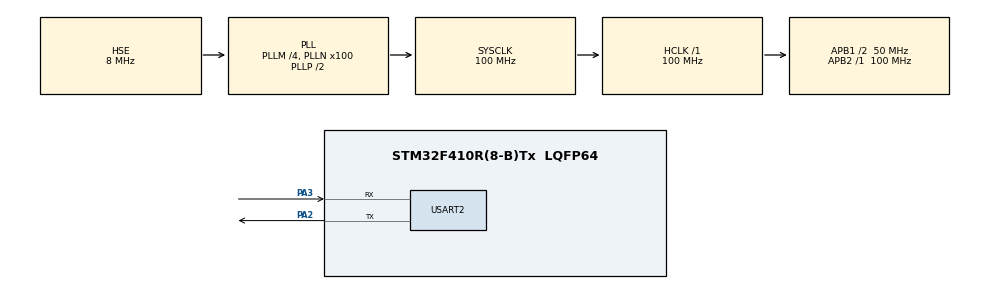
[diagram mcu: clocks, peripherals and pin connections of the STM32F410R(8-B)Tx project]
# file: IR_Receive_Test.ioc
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Mcu.Family=STM32F4
Mcu.Name=STM32F410R(8-B)Tx
Mcu.Package=LQFP64
NVIC.PriorityGroup=NVIC_PRIORITYGROUP_4
NVIC.TIM6_DAC_IRQn=true\:0\:0\:false\:false\:true\:true\:true
PA13.Mode=Serial_Wire
PA13.Signal=SYS_JTMS-SWDIO
PA14.Mode=Serial_Wire
PA14.Signal=SYS_JTCK-SWCLK
PA2.Mode=Asynchronous
PA2.Signal=USART2_TX
PA3.Mode=Asynchronous
PA3.Signal=USART2_RX
PC14-OSC32_IN.Mode=LSE-External-Oscillator
PC14-OSC32_IN.Signal=RCC_OSC32_IN
PC15-OSC32_OUT.Mode=LSE-External-Oscillator
PC15-OSC32_OUT.Signal=RCC_OSC32_OUT
PH0\ -\ OSC_IN.Mode=HSE-External-Oscillator
PH0\ -\ OSC_IN.Signal=RCC_OSC_IN
PH1\ -\ OSC_OUT.Mode=HSE-External-Oscillator
PH1\ -\ OSC_OUT.Signal=RCC_OSC_OUT
ProjectManager.HeapSize=0x200
ProjectManager.StackSize=0x400
ProjectManager.TargetToolchain=SW4STM32
RCC.48MHZClocksFreq_Value=50000000
RCC.AHBFreq_Value=100000000
RCC.APB1CLKDivider=RCC_HCLK_DIV2
RCC.APB1Freq_Value=50000000
RCC.APB1TimFreq_Value=100000000
RCC.APB2Freq_Value=100000000
RCC.APB2TimFreq_Value=100000000
RCC.CortexFreq_Value=100000000
RCC.HCLKFreq_Value=100000000
RCC.HSE_VALUE=8000000
RCC.HSI_VALUE=16000000
RCC.PLLM=4
RCC.PLLN=100
RCC.PLLSourceVirtual=RCC_PLLSOURCE_HSE
RCC.SYSCLKFreq_VALUE=100000000
RCC.SYSCLKSource=RCC_SYSCLKSOURCE_PLLCLK
RCC.VCOOutputFreq_Value=200000000
TIM6.AutoReloadPreload=TIM_AUTORELOAD_PRELOAD_ENABLE
TIM6.Period=9999
USART2.VirtualMode=VM_ASYNC
VP_TIM6_VS_ClockSourceINT.Mode=Enable_Timer
board=custom

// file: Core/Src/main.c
/* USER CODE BEGIN Header */
/**
  ******************************************************************************
  * @file           : main.c
  * @brief          : Main program body
  ******************************************************************************
  * @attention
  *
  * <h2><center>&copy; Copyright (c) 2021 STMicroelectronics.
  * All rights reserved.</center></h2>
  *
  * This software component is licensed by ST under BSD 3-Clause license,
  * the "License"; You may not use this file except in compliance with the
  * License. You may obtain a copy of the License at:
  *                        opensource.org/licenses/BSD-3-Clause
  *
  ******************************************************************************
  */
/* USER CODE END Header */
#include "main.h"

TIM_HandleTypeDef htim6;

UART_HandleTypeDef huart2;

void SystemClock_Config(void);
static void MX_GPIO_Init(void);
static void MX_TIM6_Init(void);
static void MX_USART2_UART_Init(void);

/* USER CODE BEGIN 0 */
#include <errno.h>
#include <sys/stat.h>
#include <sys/times.h>
#include <sys/unistd.h>
int _write(int file, char *ptr, int len) {
    HAL_StatusTypeDef xStatus;
    switch (file) {
    case STDOUT_FILENO: /*stdout*/
		xStatus = HAL_UART_Transmit(&huart2, (uint8_t*)ptr, len, HAL_MAX_DELAY);
		if (xStatus != HAL_OK) {
			errno = EIO;
			return -1;
		}
        break;
    case STDERR_FILENO: /* stderr */
		xStatus = HAL_UART_Transmit(&huart2, (uint8_t*)ptr, len, HAL_MAX_DELAY);
		if (xStatus != HAL_OK) {
			errno = EIO;
			return -1;
		}
        break;
    default:
        errno = EBADF;
        return -1;
    }
    return len;
}

void HAL_TIM_PeriodElapsedCallback(TIM_HandleTypeDef *htim6)
{
	static uint32_t counter = 0;
	counter++;
	if(counter >= 10000)
	{
		printf("INTERRUPT   %d !!!\r\n", counter);
		counter = 0;
	}

}

/* USER CODE END 0 */

int main(void)
{

  /* MCU Configuration--------------------------------------------------------*/

  /* Reset of all peripherals, Initializes the Flash interface and the Systick. */
  HAL_Init();

  /* Configure the system clock */
  SystemClock_Config();

  /* Initialize all configured peripherals */
  MX_GPIO_Init();
  MX_TIM6_Init();
  MX_USART2_UART_Init();
  /* USER CODE BEGIN 2 */

  HAL_TIM_Base_Start_IT(&htim6);

  /* USER CODE END 2 */

  /* Infinite loop */
  while (1)
  {

  }
}

void SystemClock_Config(void)
{
  RCC_OscInitTypeDef RCC_OscInitStruct = {0};
  RCC_ClkInitTypeDef RCC_ClkInitStruct = {0};

  /** Configure the main internal regulator output voltage
  */
  __HAL_RCC_PWR_CLK_ENABLE();
  __HAL_PWR_VOLTAGESCALING_CONFIG(PWR_REGULATOR_VOLTAGE_SCALE1);
  /** Initializes the RCC Oscillators according to the specified parameters
  * in the RCC_OscInitTypeDef structure.
  */
  RCC_OscInitStruct.OscillatorType = RCC_OSCILLATORTYPE_HSE;
  RCC_OscInitStruct.HSEState = RCC_HSE_ON;
  RCC_OscInitStruct.PLL.PLLState = RCC_PLL_ON;
  RCC_OscInitStruct.PLL.PLLSource = RCC_PLLSOURCE_HSE;
  RCC_OscInitStruct.PLL.PLLM = 4;
  RCC_OscInitStruct.PLL.PLLN = 100;
  RCC_OscInitStruct.PLL.PLLP = RCC_PLLP_DIV2;
  RCC_OscInitStruct.PLL.PLLQ = 4;
  RCC_OscInitStruct.PLL.PLLR = 2;
  if (HAL_RCC_OscConfig(&RCC_OscInitStruct) != HAL_OK)
  {
    Error_Handler();
  }
  /** Initializes the CPU, AHB and APB buses clocks
  */
  RCC_ClkInitStruct.ClockType = RCC_CLOCKTYPE_HCLK|RCC_CLOCKTYPE_SYSCLK
                              |RCC_CLOCKTYPE_PCLK1|RCC_CLOCKTYPE_PCLK2;
  RCC_ClkInitStruct.SYSCLKSource = RCC_SYSCLKSOURCE_PLLCLK;
  RCC_ClkInitStruct.AHBCLKDivider = RCC_SYSCLK_DIV1;
  RCC_ClkInitStruct.APB1CLKDivider = RCC_HCLK_DIV2;
  RCC_ClkInitStruct.APB2CLKDivider = RCC_HCLK_DIV1;

  if (HAL_RCC_ClockConfig(&RCC_ClkInitStruct, FLASH_LATENCY_3) != HAL_OK)
  {
    Error_Handler();
  }
}

static void MX_TIM6_Init(void)
{

  TIM_MasterConfigTypeDef sMasterConfig = {0};

  htim6.Instance = TIM6;
  htim6.Init.Prescaler = 0;
  htim6.Init.CounterMode = TIM_COUNTERMODE_UP;
  htim6.Init.Period = 9999;
  htim6.Init.AutoReloadPreload = TIM_AUTORELOAD_PRELOAD_ENABLE;
  if (HAL_TIM_Base_Init(&htim6) != HAL_OK)
  {
    Error_Handler();
  }
  sMasterConfig.MasterOutputTrigger = TIM_TRGO_RESET;
  sMasterConfig.MasterSlaveMode = TIM_MASTERSLAVEMODE_DISABLE;
  if (HAL_TIMEx_MasterConfigSynchronization(&htim6, &sMasterConfig) != HAL_OK)
  {
    Error_Handler();
  }

}

static void MX_USART2_UART_Init(void)
{

  huart2.Instance = USART2;
  huart2.Init.BaudRate = 115200;
  huart2.Init.WordLength = UART_WORDLENGTH_8B;
  huart2.Init.StopBits = UART_STOPBITS_1;
  huart2.Init.Parity = UART_PARITY_NONE;
  huart2.Init.Mode = UART_MODE_TX_RX;
  huart2.Init.HwFlowCtl = UART_HWCONTROL_NONE;
  huart2.Init.OverSampling = UART_OVERSAMPLING_16;
  if (HAL_UART_Init(&huart2) != HAL_OK)
  {
    Error_Handler();
  }

}

static void MX_GPIO_Init(void)
{

  /* GPIO Ports Clock Enable */
  __HAL_RCC_GPIOC_CLK_ENABLE();
  __HAL_RCC_GPIOH_CLK_ENABLE();
  __HAL_RCC_GPIOA_CLK_ENABLE();

}

void Error_Handler(void)
{
}

/************************ (C) COPYRIGHT STMicroelectronics *****END OF FILE****/
